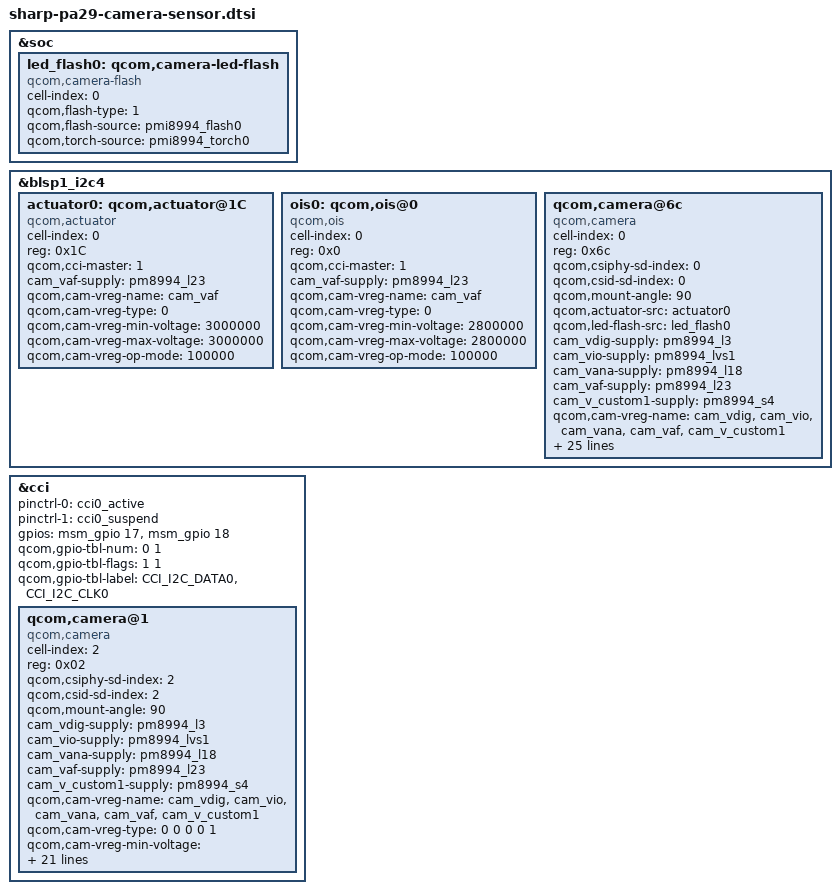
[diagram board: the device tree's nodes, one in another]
/*
 * Copyright (c) 2014, The Linux Foundation. All rights reserved.
 *
 * This program is free software; you can redistribute it and/or modify
 * it under the terms of the GNU General Public License version 2 and
 * only version 2 as published by the Free Software Foundation.
 *
 * This program is distributed in the hope that it will be useful,
 * but WITHOUT ANY WARRANTY; without even the implied warranty of
 * MERCHANTABILITY or FITNESS FOR A PARTICULAR PURPOSE.  See the
 * GNU General Public License for more details.
 */

&soc {
	led_flash0: qcom,camera-led-flash {
		cell-index = <0>;
		compatible = "qcom,camera-flash";
		qcom,flash-type = <1>;
		qcom,flash-source = <&pmi8994_flash0>;
		qcom,torch-source = <&pmi8994_torch0>;
	};
};

&blsp1_i2c4 {
	actuator0: qcom,actuator@1C {
		cell-index = <0>;
		reg = <0x1C>;
		compatible = "qcom,actuator";
		qcom,cci-master = <1>;
		cam_vaf-supply = <&pm8994_l23>;
		qcom,cam-vreg-name = "cam_vaf";
		qcom,cam-vreg-type = <0>;
		qcom,cam-vreg-min-voltage = <3000000>;
		qcom,cam-vreg-max-voltage = <3000000>;
		qcom,cam-vreg-op-mode = <100000>;
	};

	ois0: qcom,ois@0 {
		cell-index = <0>;
		reg = <0x0>;
		compatible = "qcom,ois";
		qcom,cci-master = <1>;
		cam_vaf-supply = <&pm8994_l23>;
		qcom,cam-vreg-name = "cam_vaf";
		qcom,cam-vreg-type = <0>;
		qcom,cam-vreg-min-voltage = <2800000>;
		qcom,cam-vreg-max-voltage = <2800000>;
		qcom,cam-vreg-op-mode = <100000>;
	};

	qcom,camera@6c {
		cell-index = <0>;
		compatible = "qcom,camera";
		reg = <0x6c>;
		qcom,csiphy-sd-index = <0>;
		qcom,csid-sd-index = <0>;
		qcom,mount-angle = <90>;
		qcom,actuator-src = <&actuator0>;
		qcom,led-flash-src = <&led_flash0>;
		cam_vdig-supply = <&pm8994_l3>;
		cam_vio-supply = <&pm8994_lvs1>;
		cam_vana-supply = <&pm8994_l18>;
		cam_vaf-supply = <&pm8994_l23>;
		cam_v_custom1-supply = <&pm8994_s4>;
		qcom,cam-vreg-name = "cam_vdig", "cam_vio", "cam_vana",
				     "cam_vaf", "cam_v_custom1";
		qcom,cam-custom-vreg-name = "cam_vdig", "cam_vio", "cam_vana",
				     "cam_vaf", "cam_v_custom1";
		qcom,cam-vreg-type = <0 0 0 0 1>;
		qcom,cam-vreg-min-voltage = <1200000 1800000 2800000 3000000 0>;
		qcom,cam-vreg-max-voltage = <1200000 1800000 2800000 3000000 0>;
		qcom,cam-vreg-op-mode = <105000 8000 80000 100000 0>;
		qcom,gpio-no-mux = <0>;
		pinctrl-names = "cam_default", "cam_suspend";
		pinctrl-0 = <&cam_sensor_mclk0_active &cam_sensor_rear_active>;
		pinctrl-1 = <&cam_sensor_mclk0_suspend &cam_sensor_rear_suspend>;
		gpios = <&msm_gpio 13 0>,
			<&msm_gpio 92 0>;
		qcom,gpio-reset = <1>;
		qcom,gpio-req-tbl-num = <0 1>;
		qcom,gpio-req-tbl-flags = <0 0>;
		qcom,gpio-req-tbl-label = "CAMIF_MCLK0",
					  "CAM_RESET0";
		qcom,sensor-position = <0>;
		qcom,sensor-mode = <0>;
		qcom,cci-master = <1>;
		status = "ok";
		clocks = <&clock_mmss clk_mclk0_clk_src>,
				<&clock_mmss clk_camss_mclk0_clk>;
		clock-names = "cam_src_clk", "cam_clk";
	};
};

&cci {
	pinctrl-0 = <&cci0_active>;
	pinctrl-1 = <&cci0_suspend>;
	gpios = <&msm_gpio 17 0>,
			<&msm_gpio 18 0>;
	qcom,gpio-tbl-num = <0 1>;
	qcom,gpio-tbl-flags = <1 1>;
	qcom,gpio-tbl-label = "CCI_I2C_DATA0",
					      "CCI_I2C_CLK0";

/*
	actuator0: qcom,actuator@0 {
		cell-index = <0>;
		reg = <0x0>;
		compatible = "qcom,actuator";
		qcom,cci-master = <1>;
		cam_vaf-supply = <&pm8994_l23>;
		qcom,cam-vreg-name = "cam_vaf";
		qcom,cam-vreg-type = <0>;
		qcom,cam-vreg-min-voltage = <3000000>;
		qcom,cam-vreg-max-voltage = <3000000>;
		qcom,cam-vreg-op-mode = <100000>;
	};

	ois0: qcom,ois@0 {
		cell-index = <0>;
		reg = <0x0>;
		compatible = "qcom,ois";
		qcom,cci-master = <1>;
		cam_vaf-supply = <&pm8994_l23>;
		qcom,cam-vreg-name = "cam_vaf";
		qcom,cam-vreg-type = <0>;
		qcom,cam-vreg-min-voltage = <2800000>;
		qcom,cam-vreg-max-voltage = <2800000>;
		qcom,cam-vreg-op-mode = <100000>;
	};

	qcom,camera@0 {
		cell-index = <0>;
		compatible = "qcom,camera";
		reg = <0x0>;
		qcom,csiphy-sd-index = <0>;
		qcom,csid-sd-index = <0>;
		qcom,mount-angle = <90>;
		qcom,actuator-src = <&actuator0>;
		qcom,led-flash-src = <&led_flash0>;
		cam_vdig-supply = <&pm8994_l3>;
		cam_vio-supply = <&pm8994_lvs1>;
		cam_vana-supply = <&pm8994_l18>;
		cam_vaf-supply = <&pm8994_l23>;
		cam_v_custom1-supply = <&pm8994_s4>;
		qcom,cam-vreg-name = "cam_vdig", "cam_vio", "cam_vana",
				     "cam_vaf", "cam_v_custom1";
		qcom,cam-custom-vreg-name = "cam_vdig", "cam_vio", "cam_vana",
				     "cam_vaf", "cam_v_custom1";
		qcom,cam-vreg-type = <0 0 0 0 1>;
		qcom,cam-vreg-min-voltage = <1200000 1800000 2800000 3000000 0>;
		qcom,cam-vreg-max-voltage = <1200000 1800000 2800000 3000000 0>;
		qcom,cam-vreg-op-mode = <105000 8000 80000 100000 0>;
		qcom,gpio-no-mux = <0>;
		pinctrl-names = "cam_default", "cam_suspend";
		pinctrl-0 = <&cam_sensor_mclk0_active &cam_sensor_rear_active>;
		pinctrl-1 = <&cam_sensor_mclk0_suspend &cam_sensor_rear_suspend>;
		gpios = <&msm_gpio 13 0>,
			<&msm_gpio 92 0>;
		qcom,gpio-reset = <1>;
		qcom,gpio-req-tbl-num = <0 1>;
		qcom,gpio-req-tbl-flags = <0 0>;
		qcom,gpio-req-tbl-label = "CAMIF_MCLK0",
					  "CAM_RESET0";
		qcom,sensor-position = <0>;
		qcom,sensor-mode = <0>;
		qcom,cci-master = <1>;
		status = "ok";
		clocks = <&clock_mmss clk_mclk0_clk_src>,
				<&clock_mmss clk_camss_mclk0_clk>;
		clock-names = "cam_src_clk", "cam_clk";
	};
*/
	qcom,camera@1 {
		cell-index = <2>;
		compatible = "qcom,camera";
		reg = <0x02>;
		qcom,csiphy-sd-index = <2>;
		qcom,csid-sd-index = <2>;
		qcom,mount-angle = <90>;
		cam_vdig-supply = <&pm8994_l3>;
		cam_vio-supply = <&pm8994_lvs1>;
		cam_vana-supply = <&pm8994_l18>;
		cam_vaf-supply = <&pm8994_l23>;
		cam_v_custom1-supply = <&pm8994_s4>;
		qcom,cam-vreg-name = "cam_vdig", "cam_vio", "cam_vana",
				     "cam_vaf", "cam_v_custom1";
		qcom,cam-vreg-type = <0 0 0 0 1>;
		qcom,cam-vreg-min-voltage = <1200000 1800000 2800000 3000000 0>;
		qcom,cam-vreg-max-voltage = <1200000 1800000 2800000 3000000 0>;
		qcom,cam-vreg-op-mode = <105000 8000 80000 100000 0>;

		qcom,gpio-no-mux = <0>;
		pinctrl-names = "cam_default", "cam_suspend";
		pinctrl-0 = <&cam_sensor_mclk2_active &cam_sensor_front_active>;
		pinctrl-1 = <&cam_sensor_mclk2_suspend &cam_sensor_front_suspend>;
		gpios = <&msm_gpio 15 0>,
			<&msm_gpio 104 0>;
		qcom,gpio-reset = <1>;
		qcom,gpio-req-tbl-num = <0 1>;
		qcom,gpio-req-tbl-flags = <0 0>;
		qcom,gpio-req-tbl-label = "CAMIF_MCLK2",
					  "CAM_RESET2";
		qcom,sensor-position = <1>;
		qcom,sensor-mode = <0>;
		qcom,cci-master = <0>;
		status = "ok";
		clocks = <&clock_mmss clk_mclk2_clk_src>,
			<&clock_mmss clk_camss_mclk2_clk>;
		clock-names = "cam_src_clk", "cam_clk";
	};
};
